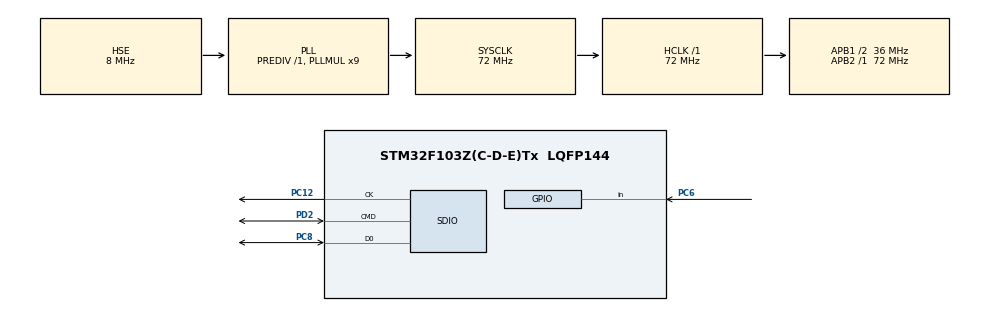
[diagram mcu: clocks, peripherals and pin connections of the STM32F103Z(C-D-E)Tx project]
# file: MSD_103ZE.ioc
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Mcu.Family=STM32F1
RCC.PLLSourceVirtual=RCC_PLLSOURCE_HSE
FATFS0.BSP.STBoard=false
FATFS0.BSP.api=Unknown
VP_FATFS_VS_SDIO.Mode=SDIO
PC12.Signal=SDIO_CK
FATFS0.BSP.mode=Input
PC8.Signal=SDIO_D0
PC6.Signal=GPIO_Input
RCC.APB1CLKDivider=RCC_HCLK_DIV2
RCC.SYSCLKSource=RCC_SYSCLKSOURCE_PLLCLK
ProjectManager.StackSize=0x400
FATFS0.BSP.instance=PC6
PA13.Signal=SYS_JTMS-SWDIO
ProjectManager.TargetToolchain=EWARM V8.32
RCC.HCLKFreq_Value=72000000
RCC.APB2TimFreq_Value=72000000
OSC_IN.Signal=RCC_OSC_IN
RCC.USBFreq_Value=72000000
OSC_OUT.Mode=HSE-External-Oscillator
SDIO.ClockDiv=1
OSC_OUT.Signal=RCC_OSC_OUT
RCC.AHBFreq_Value=72000000
FATFS0.BSP.ip=GPIO
FATFS.BSP.number=1
PD2.Mode=SD_1_bit
PC12.Mode=SD_1_bit
FATFS0.BSP.i2caddr=0
board=custom
RCC.PLLMUL=RCC_PLL_MUL9
RCC.APB2Freq_Value=72000000
PA14.Mode=Serial_Wire
PA13.Mode=Serial_Wire
Mcu.Name=STM32F103Z(C-D-E)Tx
PC8.Mode=SD_1_bit
RCC.SYSCLKFreq_VALUE=72000000
Mcu.Package=LQFP144
OSC_IN.Mode=HSE-External-Oscillator
FATFS0.BSP.solution=PC6
PA14.Signal=SYS_JTCK-SWCLK
ProjectManager.HeapSize=0x200
PC6.GPIO_PuPd=GPIO_PULLDOWN
NVIC.PriorityGroup=NVIC_PRIORITYGROUP_4
RCC.APB1TimFreq_Value=72000000
PD2.Signal=SDIO_CMD
RCC.APB1Freq_Value=36000000
FATFS0.BSP.name=Detect_SDIO

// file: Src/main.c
/* USER CODE BEGIN Header */
/**
  ******************************************************************************
  * @file           : main.c
  * @brief          : Main program body
  ******************************************************************************
  * @attention
  *
  * <h2><center>&copy; Copyright (c) 2020 STMicroelectronics.
  * All rights reserved.</center></h2>
  *
  * This software component is licensed by ST under Ultimate Liberty license
  * SLA0044, the "License"; You may not use this file except in compliance with
  * the License. You may obtain a copy of the License at:
  *                             www.st.com/SLA0044
  *
  ******************************************************************************
  */
/* USER CODE END Header */

#include "main.h"
#include "fatfs.h"

SD_HandleTypeDef hsd;

/* USER CODE BEGIN PV */
FATFS SDFatFs;  /* File system object for SD card logical drive */
FIL MyFile;     /* File object */
//char SDPath[4]; /* SD card logical drive path */
FRESULT res;                                          /* FatFs function common result code */
  uint32_t byteswritten, bytesread;                     /* File write/read counts */
  uint8_t wtext[] = "This is STM32 working with FatFs"; /* File write buffer */
  uint8_t rtext[100];
/* USER CODE END PV */

void SystemClock_Config(void);
static void MX_GPIO_Init(void);
static void MX_SDIO_SD_Init(void);

int main(void)
{

  /* MCU Configuration--------------------------------------------------------*/

  /* Reset of all peripherals, Initializes the Flash interface and the Systick. */
  HAL_Init();

  /* Configure the system clock */
  SystemClock_Config();

  /* Initialize all configured peripherals */
  MX_GPIO_Init();
  MX_SDIO_SD_Init();
  MX_FATFS_Init();
  /* USER CODE BEGIN 2 */
  if(BSP_PlatformIsDetected()){
    res=f_mount(&SDFatFs, (TCHAR const*)SDPath, 0);
    res=f_open(&MyFile, "STM32.TXT", FA_CREATE_ALWAYS | FA_WRITE);
    res = f_write(&MyFile, wtext, sizeof(wtext), (void *)&byteswritten);
    res=f_close(&MyFile);
    FATFS_UnLinkDriver(SDPath);
  }
  /* USER CODE END 2 */

  /* Infinite loop */
  while (1)
  {

  }
}

void SystemClock_Config(void)
{
  RCC_OscInitTypeDef RCC_OscInitStruct = {0};
  RCC_ClkInitTypeDef RCC_ClkInitStruct = {0};

  /** Initializes the CPU, AHB and APB busses clocks
  */
  RCC_OscInitStruct.OscillatorType = RCC_OSCILLATORTYPE_HSE;
  RCC_OscInitStruct.HSEState = RCC_HSE_ON;
  RCC_OscInitStruct.HSEPredivValue = RCC_HSE_PREDIV_DIV1;
  RCC_OscInitStruct.HSIState = RCC_HSI_ON;
  RCC_OscInitStruct.PLL.PLLState = RCC_PLL_ON;
  RCC_OscInitStruct.PLL.PLLSource = RCC_PLLSOURCE_HSE;
  RCC_OscInitStruct.PLL.PLLMUL = RCC_PLL_MUL9;
  if (HAL_RCC_OscConfig(&RCC_OscInitStruct) != HAL_OK)
  {
    Error_Handler();
  }
  /** Initializes the CPU, AHB and APB busses clocks
  */
  RCC_ClkInitStruct.ClockType = RCC_CLOCKTYPE_HCLK|RCC_CLOCKTYPE_SYSCLK
                              |RCC_CLOCKTYPE_PCLK1|RCC_CLOCKTYPE_PCLK2;
  RCC_ClkInitStruct.SYSCLKSource = RCC_SYSCLKSOURCE_PLLCLK;
  RCC_ClkInitStruct.AHBCLKDivider = RCC_SYSCLK_DIV1;
  RCC_ClkInitStruct.APB1CLKDivider = RCC_HCLK_DIV2;
  RCC_ClkInitStruct.APB2CLKDivider = RCC_HCLK_DIV1;

  if (HAL_RCC_ClockConfig(&RCC_ClkInitStruct, FLASH_LATENCY_2) != HAL_OK)
  {
    Error_Handler();
  }
}

static void MX_SDIO_SD_Init(void)
{

  hsd.Instance = SDIO;
  hsd.Init.ClockEdge = SDIO_CLOCK_EDGE_RISING;
  hsd.Init.ClockBypass = SDIO_CLOCK_BYPASS_DISABLE;
  hsd.Init.ClockPowerSave = SDIO_CLOCK_POWER_SAVE_DISABLE;
  hsd.Init.BusWide = SDIO_BUS_WIDE_1B;
  hsd.Init.HardwareFlowControl = SDIO_HARDWARE_FLOW_CONTROL_DISABLE;
  hsd.Init.ClockDiv = 1;

}

static void MX_GPIO_Init(void)
{
  GPIO_InitTypeDef GPIO_InitStruct = {0};

  /* GPIO Ports Clock Enable */
  __HAL_RCC_GPIOC_CLK_ENABLE();
  __HAL_RCC_GPIOA_CLK_ENABLE();
  __HAL_RCC_GPIOD_CLK_ENABLE();

  /*Configure GPIO pin : PC6 */
  GPIO_InitStruct.Pin = GPIO_PIN_6;
  GPIO_InitStruct.Mode = GPIO_MODE_INPUT;
  GPIO_InitStruct.Pull = GPIO_PULLDOWN;
  HAL_GPIO_Init(GPIOC, &GPIO_InitStruct);

}

void Error_Handler(void)
{
}

/************************ (C) COPYRIGHT STMicroelectronics *****END OF FILE****/
